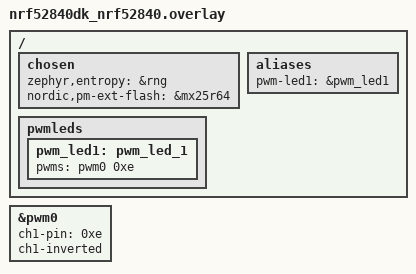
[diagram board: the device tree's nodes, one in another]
/*
 * Copyright (c) 2021 Nordic Semiconductor ASA
 *
 * SPDX-License-Identifier: LicenseRef-Nordic-5-Clause
 */

/ {
	/*
	* In some default configurations within the nRF Connect SDK,
	* e.g. on nRF52840, the chosen zephyr,entropy node is &cryptocell.
	* This devicetree overlay ensures that default is overridden wherever it
	* is set, as this application uses the RNG node for entropy exclusively.
	*/

	chosen {
		zephyr,entropy = &rng;
		nordic,pm-ext-flash = &mx25r64;
	};

	/*
	* By default, PWM module is only configured for led0 (LED1 on the board).
	* The lighting-app, however, uses LED2 to show the state of the lighting,
	* including its brightness level.
	*/
	aliases {
		pwm-led1 = &pwm_led1;
	};

	pwmleds {
		pwm_led1: pwm_led_1 {
			pwms = < &pwm0 0xe >;
		};
	};

};

&pwm0 {
	/delete-property/ ch0-pin;
	/delete-property/ ch0-inverted;
	ch1-pin = < 0xe >;
	ch1-inverted;
};
